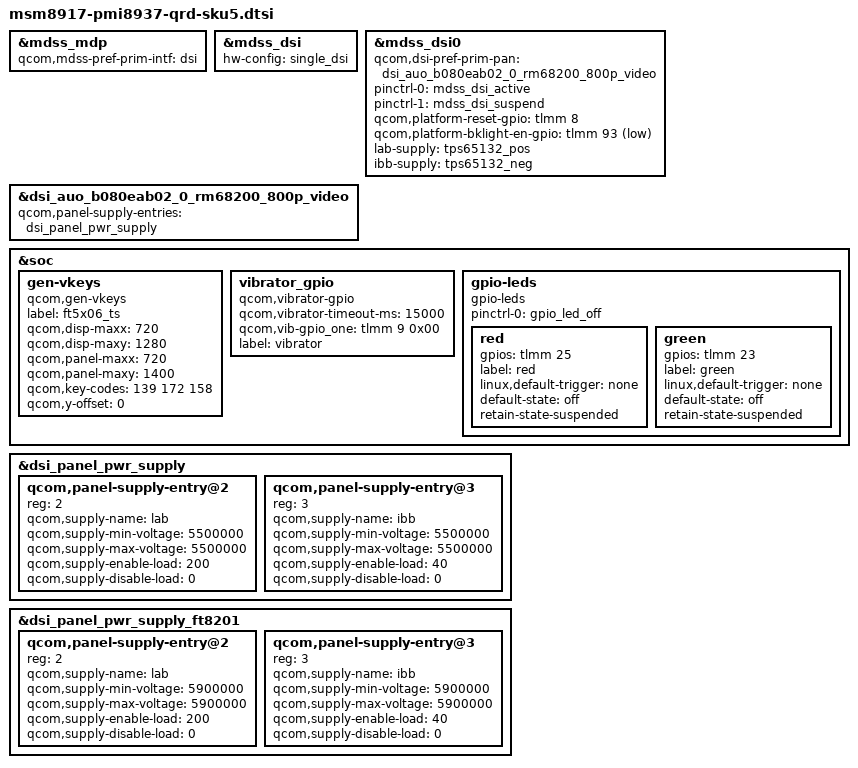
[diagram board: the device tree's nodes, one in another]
/*
 * Copyright (c) 2016, The Linux Foundation. All rights reserved.
 *
 * This program is free software; you can redistribute it and/or modify
 * it under the terms of the GNU General Public License version 2 and
 * only version 2 as published by the Free Software Foundation.
 *
 * This program is distributed in the hope that it will be useful,
 * but WITHOUT ANY WARRANTY; without even the implied warranty of
 * MERCHANTABILITY or FITNESS FOR A PARTICULAR PURPOSE.  See the
 * GNU General Public License for more details.
 */

//#include "msm-pmi8937.dtsi"
#include "msm8917-qrd.dtsi"
#include "msm8937-mdss-panels.dtsi"

&mdss_mdp {
	qcom,mdss-pref-prim-intf = "dsi";
};

&mdss_dsi {
	hw-config = "single_dsi";
};

&mdss_dsi0 {
	qcom,dsi-pref-prim-pan = <&dsi_auo_b080eab02_0_rm68200_800p_video>;
	pinctrl-names = "mdss_default", "mdss_sleep";
	pinctrl-0 = <&mdss_dsi_active>;
	pinctrl-1 = <&mdss_dsi_suspend>;

    //qcom,platform-te-gpio = <&tlmm 50 0>;
	qcom,platform-reset-gpio = <&tlmm 8 0>;
	qcom,platform-bklight-en-gpio = <&tlmm 93 1>;
    lab-supply = <&tps65132_pos>;
	ibb-supply = <&tps65132_neg>;

};

&dsi_auo_b080eab02_0_rm68200_800p_video {
	//qcom,esd-check-enabled;
	qcom,panel-supply-entries = <&dsi_panel_pwr_supply>;
};



/*
&mdss_dsi0 {
	qcom,dsi-pref-prim-pan = <&dsi_hx8394f_720p_video>;
	pinctrl-names = "mdss_default", "mdss_sleep";
	pinctrl-0 = <&mdss_dsi_active>;
	pinctrl-1 = <&mdss_dsi_suspend>;

	qcom,platform-reset-gpio = <&tlmm 60 0>;
};

&dsi_hx8394f_720p_video {
	qcom,esd-check-enabled;
	qcom,panel-supply-entries = <&dsi_panel_pwr_supply>;
};

*/

&soc {



	gen-vkeys {
		compatible = "qcom,gen-vkeys";
		label = "ft5x06_ts";
		qcom,disp-maxx = <720>;
		qcom,disp-maxy = <1280>;
		qcom,panel-maxx = <720>;
		qcom,panel-maxy = <1400>;
		qcom,key-codes = <139 172 158>;
		qcom,y-offset = <0>;
	};
		vibrator_gpio {//for vibrator
		compatible = "qcom,vibrator-gpio";
		qcom,vibrator-timeout-ms = <15000>;
		qcom,vib-gpio_one = <&tlmm 9 0x00>;
		label = "vibrator";
	};

gpio-leds {
                 compatible = "gpio-leds";
                 status = "okay";
                 pinctrl-names = "default";
                 pinctrl-0 = <&gpio_led_off>;

                 red {
                         gpios = <&tlmm 25 0>;
                         label = "red";
                         linux,default-trigger = "none";
                         default-state = "off";
                         retain-state-suspended;
                 };

                 green {
                         gpios = <&tlmm 23 0>;
                         label = "green";
                         linux,default-trigger = "none";
                         default-state = "off";
                         retain-state-suspended;
                 };
         };
};
/*
&wled {
	qcom,cons-sync-write-delay-us = <1000>;
};
&spmi_bus {
	qcom,pmi8937@2 {
		qcom,leds@a100 {
			status = "okay";
			qcom,led_mpp_2 {
				label = "mpp";
				linux,name = "green";
				linux,default-trigger = "none";
				qcom,default-state = "off";
				qcom,max-current = <40>;
				qcom,current-setting = <5>;
				qcom,id = <6>;
				qcom,mode = "manual";
				qcom,source-sel = <1>;
				qcom,mode-ctrl = <0x60>;
			};
		};
	};
};
*/

/*
&pmi_haptic {
	status = "okay";
	qcom,actuator-type = "erm";
	/delete-property/ qcom,lra-auto-res-mode;
	/delete-property/ qcom,lra-high-z;
	/delete-property/ qcom,lra-res-cal-period;
	/delete-property/ qcom,correct-lra-drive-freq;
	/delete-property/ qcom,misc-trim-error-rc19p2-clk-reg-present;
};
*/
/*
&flash_led {
	/delete-node/ qcom,flash_1;
	/delete-node/ qcom,torch_1;
};

&soc {
	led_flash0: qcom,camera-flash {
		cell-index = <0>;
		compatible = "qcom,camera-flash";
		qcom,flash-type = <1>;
		qcom,flash-source = <&pmi8937_flash0>;
		qcom,torch-source = <&pmi8937_torch0>;
		qcom,switch-source = <&pmi8937_switch>;
	};
};

/ {
	qrd_batterydata: qcom,battery-data {
		qcom,batt-id-range-pct = <15>;
		#include "batterydata-qrd-sku2-4v35-2590mah.dtsi"
	};
};

&pmi8937_charger {
	qcom,battery-data = <&qrd_batterydata>;
	qcom,float-voltage-mv = <4350>;
	qcom,chg-led-sw-controls;
	qcom,chg-led-support;
	status = "okay";
};

&pmi8937_fg {
	qcom,battery-data = <&qrd_batterydata>;
	qcom,cold-bat-decidegc = <(-100)>;
	qcom,cool-bat-decidegc = <(-100)>;
	qcom,hot-bat-decidegc = <550>;
	qcom,warm-bat-decidegc = <550>;
	qcom,bad-battery-detection-enable;
	qcom,hold-soc-while-full;
};
*/
&dsi_panel_pwr_supply {
	qcom,panel-supply-entry@2 {
		reg = <2>;
		qcom,supply-name = "lab";
		qcom,supply-min-voltage = <5500000>;
		qcom,supply-max-voltage = <5500000>;
		qcom,supply-enable-load = <200>;
		qcom,supply-disable-load = <0>;
	};

	qcom,panel-supply-entry@3 {
		reg = <3>;
		qcom,supply-name = "ibb";
		qcom,supply-min-voltage = <5500000>;
		qcom,supply-max-voltage = <5500000>;
		qcom,supply-enable-load = <40>;
		qcom,supply-disable-load = <0>;
	};
};

&dsi_panel_pwr_supply_ft8201 {
	qcom,panel-supply-entry@2 {
		reg = <2>;
		qcom,supply-name = "lab";
		qcom,supply-min-voltage = <5900000>;
		qcom,supply-max-voltage = <5900000>;
		qcom,supply-enable-load = <200>;
		qcom,supply-disable-load = <0>;
	};

	qcom,panel-supply-entry@3 {
		reg = <3>;
		qcom,supply-name = "ibb";
		qcom,supply-min-voltage = <5900000>;
		qcom,supply-max-voltage = <5900000>;
		qcom,supply-enable-load = <40>;
		qcom,supply-disable-load = <0>;
	};
};
